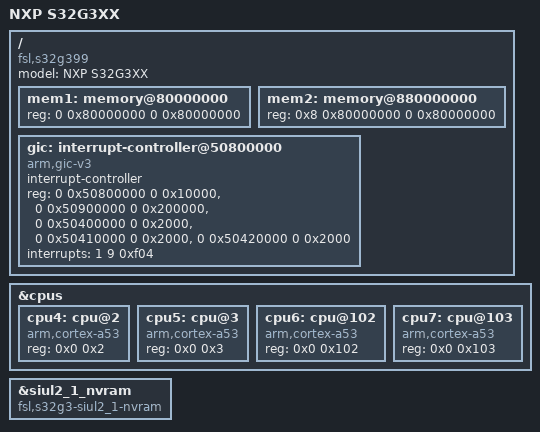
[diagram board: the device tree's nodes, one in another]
// SPDX-License-Identifier: GPL-2.0+
/*
 * Copyright 2021-2022 NXP
 *
 * This program is free software; you can redistribute it and/or modify
 * it under the terms of the GNU General Public License as published by
 * the Free Software Foundation; either version 2 of the License, or
 * (at your option) any later version.
 */

/delete-node/ &gic;
/ {
	model = "NXP S32G3XX";
	compatible = "fsl,s32g399", "fsl,s32gen1",
			"arm,vexpress,v2p-aarch64", "arm,vexpress";

	mem1: memory@80000000 {
		device_type = "memory";
		reg = <0 0x80000000 0 0x80000000>;
	};

	mem2: memory@880000000 {
		device_type = "memory";
		reg = <0x8 0x80000000 0 0x80000000>;
	};

	gic: interrupt-controller@50800000 {
		compatible = "arm,gic-v3";
		#interrupt-cells = <3>;
		#address-cells = <2>;
		#size-cells = <2>;
		interrupt-controller;
		reg = <0 0x50800000 0 0x10000>, /* GIC Dist */
		      <0 0x50900000 0 0x200000>, /* GICR (RD_base + SGI_base) */
		      <0 0x50400000 0 0x2000>, /* GICC */
		      <0 0x50410000 0 0x2000>, /* GICH */
		      <0 0x50420000 0 0x2000>; /* GICV */
		interrupts = <1 9 0xf04>;
	};
};

&cpus {
	cpu4: cpu@2 {
		device_type = "cpu";
		compatible = "arm,cortex-a53";
		reg = <0x0 0x2>;
	};

	cpu5: cpu@3 {
		device_type = "cpu";
		compatible = "arm,cortex-a53";
		reg = <0x0 0x3>;
	};

	cpu6: cpu@102 {
		device_type = "cpu";
		compatible = "arm,cortex-a53";
		reg = <0x0 0x102>;
	};

	cpu7: cpu@103 {
		device_type = "cpu";
		compatible = "arm,cortex-a53";
		reg = <0x0 0x103>;
	};
};

&siul2_1_nvram {
	compatible = "fsl,s32g3-siul2_1-nvram";
};
